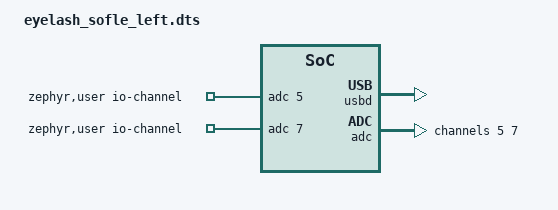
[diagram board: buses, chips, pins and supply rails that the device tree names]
/*
*
* Copyright (c) 2021 Darryl deHaan
* SPDX-License-Identifier: MIT
*
*/
#include <zephyr/dt-bindings/input/input-event-codes.h>
#include "eyelash_sofle.dtsi"

&kscan0 {
     col-gpios
         = <&gpio0 3 GPIO_ACTIVE_HIGH>
         , <&gpio0 28 GPIO_ACTIVE_HIGH>
         , <&gpio0 30 GPIO_ACTIVE_HIGH>
         , <&gpio0 21 GPIO_ACTIVE_HIGH>
         , <&gpio0 23 GPIO_ACTIVE_HIGH>
         , <&gpio0 22 GPIO_ACTIVE_HIGH>
         ;
};

zephyr_udc0: &usbd {
    status = "okay";
};

/*
		io-channel-map = <0 &adc 1>,	 // A0 = P0.3 = AIN1 
				 <1 &adc 2>,	 // A1 = P0.4 = AIN2 
				 <2 &adc 4>,	 // A2 = P0.28 = AIN4 
				 <3 &adc 5>,	 // A3 = P0.29 = AIN5 
				 <4 &adc 6>,	 // A4 = P0.30 = AIN6 
				 <5 &adc 7>;	 // A5 = P0.31 = AIN7 
*/

/ {
	  zephyr,user {
		io-channels = <&adc 5>, <&adc 7>;
	};
};

&adc {
	#address-cells = <1>;
	#size-cells = <0>;

	channel@5 {
		reg = <5>;
		zephyr,gain = "ADC_GAIN_1_6";
		zephyr,reference = "ADC_REF_INTERNAL";
		zephyr,acquisition-time = <ADC_ACQ_TIME_DEFAULT>;
		zephyr,input-positive = <NRF_SAADC_AIN5>; /* P0.29 */
		zephyr,resolution = <12>;
	};

	channel@7 {
		reg = <7>;
		zephyr,gain = "ADC_GAIN_1_6";
		zephyr,reference = "ADC_REF_INTERNAL";
		zephyr,acquisition-time = <ADC_ACQ_TIME_DEFAULT>;
		zephyr,input-positive = <NRF_SAADC_AIN7>; /* P1.03 */
		zephyr,resolution = <12>;
	};
};

&adc {
    status = "okay";
};


/ {
	anin0: analog_input_0 {
		compatible = "zmk,analog-input";
		sampling-hz = <100>;
		x-ch {
			io-channels = <&adc 5>;
			mv-mid = <1630>;
			mv-min-max = <1600>;
			mv-deadzone = <10>;
			scale-multiplier = <1>;
			scale-divisor = <70>;
			invert;
			evt-type = <INPUT_EV_REL>;
			input-code = <INPUT_REL_X>;
		};
		y-ch {
			io-channels = <&adc 7>;
			mv-mid = <1630>;
			mv-min-max = <1600>;
			mv-deadzone = <10>;
			scale-multiplier = <3>;
			scale-divisor = <4>;
			invert;
			evt-type = <INPUT_EV_REL>;
			input-code = <INPUT_REL_Y>;

			/* enable report mdoe for gamepad axix or knob */
			/* to only call input_report on quantquantized value is updated */
			/* report-on-change-only; */

		};
	};
};
